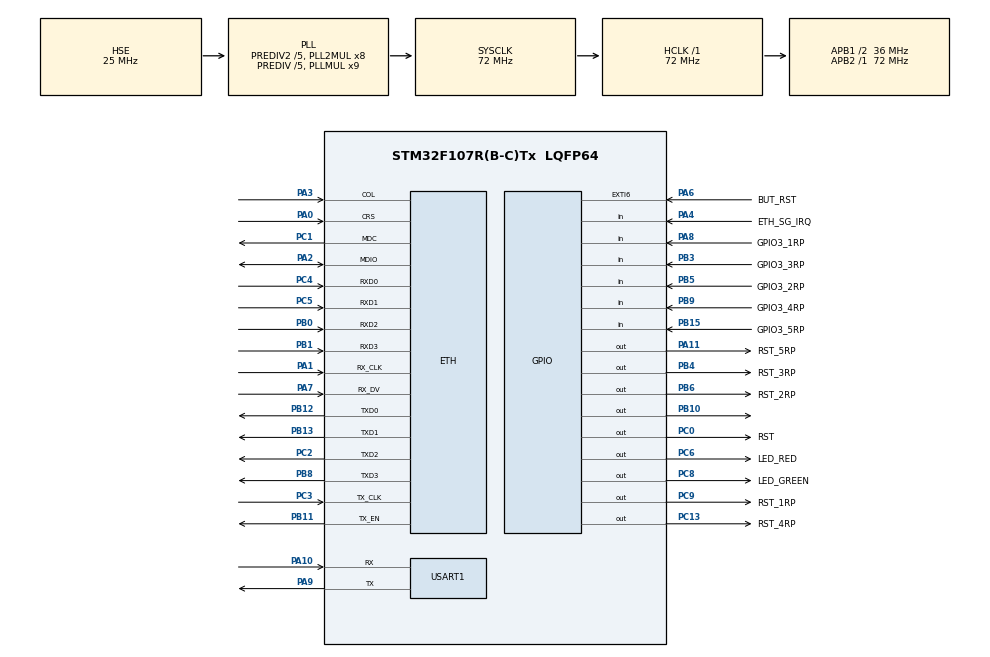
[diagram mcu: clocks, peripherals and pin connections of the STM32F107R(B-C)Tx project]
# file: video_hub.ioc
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Dma.Request0=USART1_TX
Dma.USART1_TX.0.Direction=DMA_MEMORY_TO_PERIPH
Dma.USART1_TX.0.Instance=DMA1_Channel4
Dma.USART1_TX.0.MemDataAlignment=DMA_MDATAALIGN_BYTE
Dma.USART1_TX.0.MemInc=DMA_MINC_ENABLE
Dma.USART1_TX.0.Mode=DMA_NORMAL
Dma.USART1_TX.0.PeriphDataAlignment=DMA_PDATAALIGN_BYTE
Dma.USART1_TX.0.PeriphInc=DMA_PINC_DISABLE
Dma.USART1_TX.0.Priority=DMA_PRIORITY_LOW
ETH.MACAddr=00\:80\:E1\:AA\:78\:00
ETH.MediaInterface=ETH_MEDIA_INTERFACE_MII
IWDG.Prescaler=IWDG_PRESCALER_64
LWIP.GATEWAY_ADDRESS=192.168.001.001
LWIP.IP_ADDRESS=192.168.001.235
LWIP.LWIP_DHCP=0
LWIP.NETMASK_ADDRESS=255.255.255.000
LWIP.TCP_WND_UPDATE_THRESHOLD=536
LWIP.Version=v2.0.0_Cube
Mcu.Family=STM32F1
Mcu.Name=STM32F107R(B-C)Tx
Mcu.Package=LQFP64
NVIC.DMA1_Channel4_IRQn=true\:0\:0\:false\:false\:true\:false
NVIC.EXTI9_5_IRQn=true\:0\:0\:false\:false\:true\:true
NVIC.PriorityGroup=NVIC_PRIORITYGROUP_4
NVIC.USART1_IRQn=true\:0\:0\:false\:false\:true\:true
PA0-WKUP.Mode=MII
PA0-WKUP.Signal=ETH_CRS
PA1.Mode=MII
PA1.Signal=ETH_RX_CLK
PA10.Mode=Asynchronous
PA10.Signal=USART1_RX
PA11.GPIO_Label=RST_5RP
PA11.GPIO_ModeDefaultOutputPP=GPIO_MODE_OUTPUT_PP
PA11.GPIO_Speed=GPIO_SPEED_FREQ_HIGH
PA11.PinState=GPIO_PIN_SET
PA11.Signal=GPIO_Output
PA13.Mode=Serial_Wire
PA13.Signal=SYS_JTMS-SWDIO
PA14.Mode=Serial_Wire
PA14.Signal=SYS_JTCK-SWCLK
PA2.Mode=MII
PA2.Signal=ETH_MDIO
PA3.Mode=MII
PA3.Signal=ETH_COL
PA4.GPIO_Label=ETH_SG_IRQ
PA4.GPIO_PuPd=GPIO_PULLUP
PA4.Signal=GPIO_Input
PA6.GPIO_Label=BUT_RST
PA6.GPIO_ModeDefaultEXTI=GPIO_MODE_IT_FALLING
PA6.Signal=GPXTI6
PA7.Mode=MII
PA7.Signal=ETH_RX_DV
PA8.GPIO_Label=GPIO3_1RP
PA8.GPIO_PuPd=GPIO_PULLUP
PA8.Signal=GPIO_Input
PA9.Mode=Asynchronous
PA9.Signal=USART1_TX
PB0.Mode=MII
PB0.Signal=ETH_RXD2
PB1.Mode=MII
PB1.Signal=ETH_RXD3
PB10.Signal=GPIO_Output
PB11.Mode=MII
PB11.Signal=ETH_TX_EN
PB12.Mode=MII
PB12.Signal=ETH_TXD0
PB13.Mode=MII
PB13.Signal=ETH_TXD1
PB15.GPIO_Label=GPIO3_5RP
PB15.GPIO_PuPd=GPIO_PULLUP
PB15.Signal=GPIO_Input
PB3.GPIO_Label=GPIO3_3RP
PB3.GPIO_PuPd=GPIO_PULLUP
PB3.Signal=GPIO_Input
PB4.GPIO_Label=RST_3RP
PB4.GPIO_ModeDefaultOutputPP=GPIO_MODE_OUTPUT_PP
PB4.GPIO_Speed=GPIO_SPEED_FREQ_HIGH
PB4.PinState=GPIO_PIN_SET
PB4.Signal=GPIO_Output
PB5.GPIO_Label=GPIO3_2RP
PB5.GPIO_PuPd=GPIO_PULLUP
PB5.Signal=GPIO_Input
PB6.GPIO_Label=RST_2RP
PB6.GPIO_ModeDefaultOutputPP=GPIO_MODE_OUTPUT_PP
PB6.GPIO_Speed=GPIO_SPEED_FREQ_HIGH
PB6.PinState=GPIO_PIN_SET
PB6.Signal=GPIO_Output
PB8.Mode=MII
PB8.Signal=ETH_TXD3
PB9.GPIO_Label=GPIO3_4RP
PB9.GPIO_PuPd=GPIO_PULLUP
PB9.Signal=GPIO_Input
PC0.GPIO_Label=RST
PC0.PinState=GPIO_PIN_SET
PC0.Signal=GPIO_Output
PC1.Mode=MII
PC1.Signal=ETH_MDC
PC13-TAMPER-RTC.GPIO_Label=RST_4RP
PC13-TAMPER-RTC.GPIO_ModeDefaultOutputPP=GPIO_MODE_OUTPUT_PP
PC13-TAMPER-RTC.GPIO_Speed=GPIO_SPEED_FREQ_HIGH
PC13-TAMPER-RTC.PinState=GPIO_PIN_SET
PC13-TAMPER-RTC.Signal=GPIO_Output
PC2.Mode=MII
PC2.Signal=ETH_TXD2
PC3.Mode=MII
PC3.Signal=ETH_TX_CLK
PC4.Mode=MII
PC4.Signal=ETH_RXD0
PC5.Mode=MII
PC5.Signal=ETH_RXD1
PC6.GPIO_Label=LED_RED
PC6.PinState=GPIO_PIN_SET
PC6.Signal=GPIO_Output
PC8.GPIO_Label=LED_GREEN
PC8.PinState=GPIO_PIN_SET
PC8.Signal=GPIO_Output
PC9.GPIO_Label=RST_1RP
PC9.GPIO_ModeDefaultOutputPP=GPIO_MODE_OUTPUT_PP
PC9.GPIO_Speed=GPIO_SPEED_FREQ_HIGH
PC9.PinState=GPIO_PIN_SET
PC9.Signal=GPIO_Output
PD0-OSC_IN.Mode=HSE-External-Oscillator
PD0-OSC_IN.Signal=RCC_OSC_IN
PD1-OSC_OUT.Mode=HSE-External-Oscillator
PD1-OSC_OUT.Signal=RCC_OSC_OUT
ProjectManager.HeapSize=0x200
ProjectManager.StackSize=0x400
ProjectManager.TargetToolchain=TrueSTUDIO
RCC.AHBFreq_Value=72000000
RCC.APB1CLKDivider=RCC_HCLK_DIV2
RCC.APB1Freq_Value=36000000
RCC.APB1TimFreq_Value=72000000
RCC.APB2Freq_Value=72000000
RCC.APB2TimFreq_Value=72000000
RCC.HCLKFreq_Value=72000000
RCC.HSEDivPLL=RCC_HSE_PREDIV_DIV5
RCC.HSE_VALUE=25000000
RCC.PLLMUL=RCC_PLL_MUL9
RCC.PLLSourceVirtual=RCC_PLLSOURCE_HSE
RCC.Prediv1Source=RCC_PREDIV1_SOURCE_PLL2
RCC.Prediv2=RCC_HSE_PREDIV2_DIV5
RCC.SYSCLKFreq_VALUE=72000000
RCC.SYSCLKSource=RCC_SYSCLKSOURCE_PLLCLK
RCC.USBFreq_Value=48000000
USART1.VirtualMode=VM_ASYNC
VP_CRC_VS_CRC.Mode=CRC_Activate
VP_IWDG_VS_IWDG.Mode=IWDG_Activate
VP_LWIP_VS_Enabled.Mode=Enabled
board=video_hub

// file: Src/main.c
/**
  ******************************************************************************
  * @file           : main.c
  * @brief          : Main program body
  ******************************************************************************
  * This notice applies to any and all portions of this file
  * that are not between comment pairs USER CODE BEGIN and
  * USER CODE END. Other portions of this file, whether
  * inserted by the user or by software development tools
  * are owned by their respective copyright owners.
  *
  * Copyright (c) 2018 STMicroelectronics International N.V.
  * All rights reserved.
  *
  * Redistribution and use in source and binary forms, with or without
  * modification, are permitted, provided that the following conditions are met:
  *
  * 1. Redistribution of source code must retain the above copyright notice,
  *    this list of conditions and the following disclaimer.
  * 2. Redistributions in binary form must reproduce the above copyright notice,
  *    this list of conditions and the following disclaimer in the documentation
  *    and/or other materials provided with the distribution.
  * 3. Neither the name of STMicroelectronics nor the names of other
  *    contributors to this software may be used to endorse or promote products
  *    derived from this software without specific written permission.
  * 4. This software, including modifications and/or derivative works of this
  *    software, must execute solely and exclusively on microcontroller or
  *    microprocessor devices manufactured by or for STMicroelectronics.
  * 5. Redistribution and use of this software other than as permitted under
  *    this license is void and will automatically terminate your rights under
  *    this license.
  *
  * THIS SOFTWARE IS PROVIDED BY STMICROELECTRONICS AND CONTRIBUTORS "AS IS"
  * AND ANY EXPRESS, IMPLIED OR STATUTORY WARRANTIES, INCLUDING, BUT NOT
  * LIMITED TO, THE IMPLIED WARRANTIES OF MERCHANTABILITY, FITNESS FOR A
  * PARTICULAR PURPOSE AND NON-INFRINGEMENT OF THIRD PARTY INTELLECTUAL PROPERTY
  * RIGHTS ARE DISCLAIMED TO THE FULLEST EXTENT PERMITTED BY LAW. IN NO EVENT
  * SHALL STMICROELECTRONICS OR CONTRIBUTORS BE LIABLE FOR ANY DIRECT, INDIRECT,
  * INCIDENTAL, SPECIAL, EXEMPLARY, OR CONSEQUENTIAL DAMAGES (INCLUDING, BUT NOT
  * LIMITED TO, PROCUREMENT OF SUBSTITUTE GOODS OR SERVICES; LOSS OF USE, DATA,
  * OR PROFITS; OR BUSINESS INTERRUPTION) HOWEVER CAUSED AND ON ANY THEORY OF
  * LIABILITY, WHETHER IN CONTRACT, STRICT LIABILITY, OR TORT (INCLUDING
  * NEGLIGENCE OR OTHERWISE) ARISING IN ANY WAY OUT OF THE USE OF THIS SOFTWARE,
  * EVEN IF ADVISED OF THE POSSIBILITY OF SUCH DAMAGE.
  *
  ******************************************************************************
  */
#include "main.h"
#include "stm32f1xx_hal.h"
#include "lwip.h"

/* USER CODE BEGIN Includes */
#include "stm32f1xx_hal_crc.h"
#include "app.h"
/* USER CODE END Includes */

CRC_HandleTypeDef hcrc;

IWDG_HandleTypeDef hiwdg;

UART_HandleTypeDef huart1;
DMA_HandleTypeDef hdma_usart1_tx;

/* USER CODE BEGIN PV */
/* Private variables ---------------------------------------------------------*/

/* USER CODE END PV */

void SystemClock_Config(void);
static void MX_GPIO_Init(void);
static void MX_DMA_Init(void);
static void MX_USART1_UART_Init(void);
static void MX_CRC_Init(void);
static void MX_IWDG_Init(void);

/* USER CODE BEGIN PFP */
/* Private function prototypes -----------------------------------------------*/

/* USER CODE END PFP */

int main(void)
{
  /* USER CODE BEGIN 1 */
#ifdef RELEASE
	__disable_irq();
	SCB->VTOR = 0x8008000; //только для процессоров старше чем М0
	__enable_irq();
#endif
  /* USER CODE END 1 */

  /* MCU Configuration----------------------------------------------------------*/

  /* Reset of all peripherals, Initializes the Flash interface and the Systick. */
  HAL_Init();

  /* Configure the system clock */
  SystemClock_Config();

  /* Initialize all configured peripherals */
  MX_GPIO_Init();
  MX_DMA_Init();
  MX_USART1_UART_Init();
  MX_CRC_Init();
  //MX_LWIP_Init();
#ifdef RELEASE
  MX_IWDG_Init();
#endif
  /* USER CODE BEGIN 2 */
  app_init();
  /* USER CODE END 2 */

  /* Infinite loop */
  /* USER CODE BEGIN WHILE */
  while (1)
  {
	  app_step();
  /* USER CODE END WHILE */

  }

}

void SystemClock_Config(void)
{

  RCC_OscInitTypeDef RCC_OscInitStruct;
  RCC_ClkInitTypeDef RCC_ClkInitStruct;

    /**Initializes the CPU, AHB and APB busses clocks
    */
  RCC_OscInitStruct.OscillatorType = RCC_OSCILLATORTYPE_LSI|RCC_OSCILLATORTYPE_HSE;
  RCC_OscInitStruct.HSEState = RCC_HSE_ON;
  RCC_OscInitStruct.HSEPredivValue = RCC_HSE_PREDIV_DIV5;
  RCC_OscInitStruct.HSIState = RCC_HSI_ON;
  RCC_OscInitStruct.LSIState = RCC_LSI_ON;
  RCC_OscInitStruct.Prediv1Source = RCC_PREDIV1_SOURCE_PLL2;
  RCC_OscInitStruct.PLL.PLLState = RCC_PLL_ON;
  RCC_OscInitStruct.PLL.PLLSource = RCC_PLLSOURCE_HSE;
  RCC_OscInitStruct.PLL.PLLMUL = RCC_PLL_MUL9;
  RCC_OscInitStruct.PLL2.PLL2State = RCC_PLL2_ON;
  RCC_OscInitStruct.PLL2.PLL2MUL = RCC_PLL2_MUL8;
  RCC_OscInitStruct.PLL2.HSEPrediv2Value = RCC_HSE_PREDIV2_DIV5;
  if (HAL_RCC_OscConfig(&RCC_OscInitStruct) != HAL_OK)
  {
    _Error_Handler(__FILE__, __LINE__);
  }

    /**Initializes the CPU, AHB and APB busses clocks
    */
  RCC_ClkInitStruct.ClockType = RCC_CLOCKTYPE_HCLK|RCC_CLOCKTYPE_SYSCLK
                              |RCC_CLOCKTYPE_PCLK1|RCC_CLOCKTYPE_PCLK2;
  RCC_ClkInitStruct.SYSCLKSource = RCC_SYSCLKSOURCE_PLLCLK;
  RCC_ClkInitStruct.AHBCLKDivider = RCC_SYSCLK_DIV1;
  RCC_ClkInitStruct.APB1CLKDivider = RCC_HCLK_DIV2;
  RCC_ClkInitStruct.APB2CLKDivider = RCC_HCLK_DIV1;

  if (HAL_RCC_ClockConfig(&RCC_ClkInitStruct, FLASH_LATENCY_2) != HAL_OK)
  {
    _Error_Handler(__FILE__, __LINE__);
  }

    /**Configure the Systick interrupt time
    */
  HAL_SYSTICK_Config(HAL_RCC_GetHCLKFreq()/1000);

    /**Configure the Systick
    */
  HAL_SYSTICK_CLKSourceConfig(SYSTICK_CLKSOURCE_HCLK);

    /**Configure the Systick interrupt time
    */
  __HAL_RCC_PLLI2S_ENABLE();

  /* SysTick_IRQn interrupt configuration */
  HAL_NVIC_SetPriority(SysTick_IRQn, 0, 0);
}

/* CRC init function */
static void MX_CRC_Init(void)
{

  hcrc.Instance = CRC;
  if (HAL_CRC_Init(&hcrc) != HAL_OK)
  {
    _Error_Handler(__FILE__, __LINE__);
  }

}

/* IWDG init function */
static void MX_IWDG_Init(void)
{

  hiwdg.Instance = IWDG;
  hiwdg.Init.Prescaler = IWDG_PRESCALER_64;
  hiwdg.Init.Reload = 4095;
  if (HAL_IWDG_Init(&hiwdg) != HAL_OK)
  {
    _Error_Handler(__FILE__, __LINE__);
  }

}

/* USART1 init function */
static void MX_USART1_UART_Init(void)
{

  huart1.Instance = USART1;
  huart1.Init.BaudRate = 115200;
  huart1.Init.WordLength = UART_WORDLENGTH_8B;
  huart1.Init.StopBits = UART_STOPBITS_1;
  huart1.Init.Parity = UART_PARITY_NONE;
  huart1.Init.Mode = UART_MODE_TX_RX;
  huart1.Init.HwFlowCtl = UART_HWCONTROL_NONE;
  huart1.Init.OverSampling = UART_OVERSAMPLING_16;
  if (HAL_UART_Init(&huart1) != HAL_OK)
  {
    _Error_Handler(__FILE__, __LINE__);
  }

}

static void MX_DMA_Init(void)
{
  /* DMA controller clock enable */
  __HAL_RCC_DMA1_CLK_ENABLE();

  /* DMA interrupt init */
  /* DMA1_Channel4_IRQn interrupt configuration */
  HAL_NVIC_SetPriority(DMA1_Channel4_IRQn, 0, 0);
  HAL_NVIC_EnableIRQ(DMA1_Channel4_IRQn);

}

/** Configure pins as
        * Analog
        * Input
        * Output
        * EVENT_OUT
        * EXTI
*/
static void MX_GPIO_Init(void)
{

  GPIO_InitTypeDef GPIO_InitStruct;

  /* GPIO Ports Clock Enable */
  __HAL_RCC_GPIOC_CLK_ENABLE();
  __HAL_RCC_GPIOD_CLK_ENABLE();
  __HAL_RCC_GPIOA_CLK_ENABLE();
  __HAL_RCC_GPIOB_CLK_ENABLE();

  /*Configure GPIO pin Output Level */
  HAL_GPIO_WritePin(GPIOC, RST_4RP_Pin|RST_Pin|LED_RED_Pin|LED_GREEN_Pin
                          |RST_1RP_Pin, GPIO_PIN_SET);

  /*Configure GPIO pin Output Level */
  HAL_GPIO_WritePin(GPIOB, GPIO_PIN_10, GPIO_PIN_RESET);

  /*Configure GPIO pin Output Level */
  HAL_GPIO_WritePin(RST_5RP_GPIO_Port, RST_5RP_Pin, GPIO_PIN_SET);

  /*Configure GPIO pin Output Level */
  HAL_GPIO_WritePin(GPIOB, RST_3RP_Pin|RST_2RP_Pin, GPIO_PIN_SET);

  /*Configure GPIO pins : RST_4RP_Pin RST_1RP_Pin */
  GPIO_InitStruct.Pin = RST_4RP_Pin|RST_1RP_Pin;
  GPIO_InitStruct.Mode = GPIO_MODE_OUTPUT_PP;
  GPIO_InitStruct.Pull = GPIO_NOPULL;
  GPIO_InitStruct.Speed = GPIO_SPEED_FREQ_HIGH;
  HAL_GPIO_Init(GPIOC, &GPIO_InitStruct);

  /*Configure GPIO pins : RST_Pin LED_RED_Pin LED_GREEN_Pin */
  GPIO_InitStruct.Pin = RST_Pin|LED_RED_Pin|LED_GREEN_Pin;
  GPIO_InitStruct.Mode = GPIO_MODE_OUTPUT_PP;
  GPIO_InitStruct.Pull = GPIO_NOPULL;
  GPIO_InitStruct.Speed = GPIO_SPEED_FREQ_LOW;
  HAL_GPIO_Init(GPIOC, &GPIO_InitStruct);

  /*Configure GPIO pins : ETH_SG_IRQ_Pin GPIO3_1RP_Pin */
  GPIO_InitStruct.Pin = ETH_SG_IRQ_Pin|GPIO3_1RP_Pin;
  GPIO_InitStruct.Mode = GPIO_MODE_INPUT;
  GPIO_InitStruct.Pull = GPIO_PULLUP;
  HAL_GPIO_Init(GPIOA, &GPIO_InitStruct);

  /*Configure GPIO pin : BUT_RST_Pin */
  GPIO_InitStruct.Pin = BUT_RST_Pin;
  GPIO_InitStruct.Mode = GPIO_MODE_IT_FALLING;
  GPIO_InitStruct.Pull = GPIO_NOPULL;
  HAL_GPIO_Init(BUT_RST_GPIO_Port, &GPIO_InitStruct);

  /*Configure GPIO pin : PB10 */
  GPIO_InitStruct.Pin = GPIO_PIN_10;
  GPIO_InitStruct.Mode = GPIO_MODE_OUTPUT_PP;
  GPIO_InitStruct.Pull = GPIO_NOPULL;
  GPIO_InitStruct.Speed = GPIO_SPEED_FREQ_LOW;
  HAL_GPIO_Init(GPIOB, &GPIO_InitStruct);

  /*Configure GPIO pins : GPIO3_5RP_Pin GPIO3_3RP_Pin GPIO3_2RP_Pin GPIO3_4RP_Pin */
  GPIO_InitStruct.Pin = GPIO3_5RP_Pin|GPIO3_3RP_Pin|GPIO3_2RP_Pin|GPIO3_4RP_Pin;
  GPIO_InitStruct.Mode = GPIO_MODE_INPUT;
  GPIO_InitStruct.Pull = GPIO_PULLUP;
  HAL_GPIO_Init(GPIOB, &GPIO_InitStruct);

  /*Configure GPIO pin : RST_5RP_Pin */
  GPIO_InitStruct.Pin = RST_5RP_Pin;
  GPIO_InitStruct.Mode = GPIO_MODE_OUTPUT_PP;
  GPIO_InitStruct.Pull = GPIO_NOPULL;
  GPIO_InitStruct.Speed = GPIO_SPEED_FREQ_HIGH;
  HAL_GPIO_Init(RST_5RP_GPIO_Port, &GPIO_InitStruct);

  /*Configure GPIO pins : RST_3RP_Pin RST_2RP_Pin */
  GPIO_InitStruct.Pin = RST_3RP_Pin|RST_2RP_Pin;
  GPIO_InitStruct.Mode = GPIO_MODE_OUTPUT_PP;
  GPIO_InitStruct.Pull = GPIO_NOPULL;
  GPIO_InitStruct.Speed = GPIO_SPEED_FREQ_HIGH;
  HAL_GPIO_Init(GPIOB, &GPIO_InitStruct);

  /* EXTI interrupt init*/
  HAL_NVIC_SetPriority(EXTI9_5_IRQn, 0, 0);
  HAL_NVIC_EnableIRQ(EXTI9_5_IRQn);

}

void _Error_Handler(char *file, int line)
{
  while(1)
  {
  }
}

/************************ (C) COPYRIGHT STMicroelectronics *****END OF FILE****/
